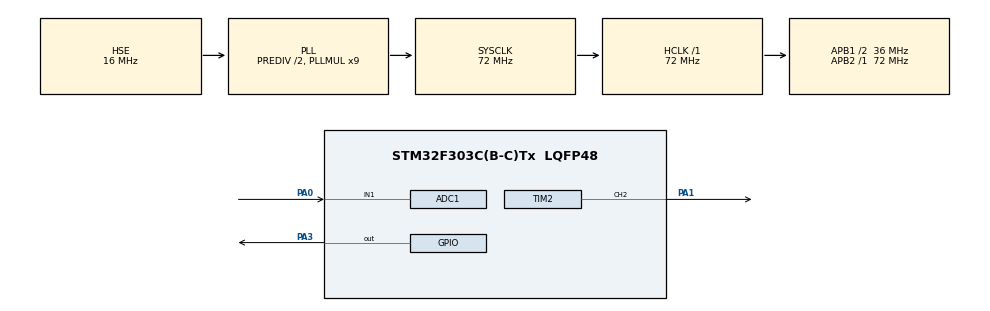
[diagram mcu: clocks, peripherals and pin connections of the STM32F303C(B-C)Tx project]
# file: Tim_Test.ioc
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ADC1.Channel-0\#ChannelRegularConversion=ADC_CHANNEL_1
ADC1.DMAContinuousRequests=ENABLE
ADC1.ExternalTrigConv=ADC_EXTERNALTRIGCONV_T3_TRGO
ADC1.NbrOfConversionFlag=1
ADC1.Offset-0\#ChannelRegularConversion=0
ADC1.OffsetNumber-0\#ChannelRegularConversion=ADC_OFFSET_NONE
ADC1.Rank-0\#ChannelRegularConversion=1
ADC1.SamplingTime-0\#ChannelRegularConversion=ADC_SAMPLETIME_1CYCLE_5
ADC1.SamplingTimeOPAMP-0\#ChannelRegularConversion=ADC_SAMPLETIME_61CYCLES_5
ADC1.master=1
Dma.ADC1.0.Direction=DMA_PERIPH_TO_MEMORY
Dma.ADC1.0.Instance=DMA1_Channel1
Dma.ADC1.0.MemDataAlignment=DMA_MDATAALIGN_HALFWORD
Dma.ADC1.0.MemInc=DMA_MINC_ENABLE
Dma.ADC1.0.Mode=DMA_CIRCULAR
Dma.ADC1.0.PeriphDataAlignment=DMA_PDATAALIGN_HALFWORD
Dma.ADC1.0.PeriphInc=DMA_PINC_DISABLE
Dma.ADC1.0.Priority=DMA_PRIORITY_LOW
Dma.Request0=ADC1
Mcu.Family=STM32F3
Mcu.Name=STM32F303C(B-C)Tx
Mcu.Package=LQFP48
NVIC.ADC1_2_IRQn=true\:0\:0\:false\:false\:true\:true\:true\:true
NVIC.DMA1_Channel1_IRQn=true\:0\:0\:false\:false\:true\:false\:true\:true
NVIC.PriorityGroup=NVIC_PRIORITYGROUP_4
PA0.Mode=IN1-Single-Ended
PA0.Signal=ADC1_IN1
PA1.GPIO_Speed=GPIO_SPEED_FREQ_HIGH
PA1.Signal=S_TIM2_CH2
PA3.Signal=GPIO_Output
PF0-OSC_IN.Mode=HSE-External-Oscillator
PF0-OSC_IN.Signal=RCC_OSC_IN
PF1-OSC_OUT.Mode=HSE-External-Oscillator
PF1-OSC_OUT.Signal=RCC_OSC_OUT
ProjectManager.HeapSize=0x200
ProjectManager.StackSize=0x400
ProjectManager.TargetToolchain=STM32CubeIDE
RCC.AHBFreq_Value=72000000
RCC.APB1CLKDivider=RCC_HCLK_DIV2
RCC.APB1Freq_Value=36000000
RCC.APB1TimFreq_Value=72000000
RCC.APB2Freq_Value=72000000
RCC.APB2TimFreq_Value=72000000
RCC.CortexFreq_Value=72000000
RCC.HCLKFreq_Value=72000000
RCC.HSE_VALUE=16000000
RCC.HSI_VALUE=8000000
RCC.LSE_VALUE=32768
RCC.PLLMUL=RCC_PLL_MUL9
RCC.PLLSourceVirtual=RCC_PLLSOURCE_HSE
RCC.RCC_PLLsource_Clock_Source_FROM_HSE=RCC_HSE_PREDIV_DIV2
RCC.SYSCLKFreq_VALUE=72000000
RCC.SYSCLKSourceVirtual=RCC_SYSCLKSOURCE_PLLCLK
RCC.USBFreq_Value=72000000
SH.S_TIM2_CH2.0=TIM2_CH2,PWM Generation2 CH2
TIM2.Channel-PWM\ Generation2\ CH2=TIM_CHANNEL_2
TIM2.Period=0
TIM3.Period=0
TIM3.TIM_MasterOutputTrigger=TIM_TRGO_UPDATE
VP_TIM2_VS_ClockSourceINT.Mode=Internal
VP_TIM3_VS_ClockSourceINT.Mode=Internal
board=custom

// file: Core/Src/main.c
/* USER CODE BEGIN Header */
/**
  ******************************************************************************
  * @file           : main.c
  * @brief          : Main program body
  ******************************************************************************
  * @attention
  *
  * Copyright (c) 2024 STMicroelectronics.
  * All rights reserved.
  *
  * This software is licensed under terms that can be found in the LICENSE file
  * in the root directory of this software component.
  * If no LICENSE file comes with this software, it is provided AS-IS.
  *
  ******************************************************************************
  */
/* USER CODE END Header */
#include "main.h"
#include "adc.h"
#include "dma.h"
#include "tim.h"
#include "gpio.h"

/* USER CODE BEGIN PV */
uint16_t data[10];
/* USER CODE END PV */

void SystemClock_Config(void);

int main(void)
{

  /* MCU Configuration--------------------------------------------------------*/

  /* Reset of all peripherals, Initializes the Flash interface and the Systick. */
  HAL_Init();

  /* Configure the system clock */
  SystemClock_Config();

  /* Initialize all configured peripherals */
  MX_GPIO_Init();
  MX_DMA_Init();
  MX_TIM2_Init();
  MX_ADC1_Init();
  MX_TIM3_Init();
  /* USER CODE BEGIN 2 */
  TIM2->ARR = 72-1;
  TIM2->PSC = 0;
  TIM2->CCR2 = 36-1;
  HAL_TIM_PWM_Start(&htim2, TIM_CHANNEL_2);

  HAL_GPIO_WritePin(GPIOA, GPIO_PIN_3, GPIO_PIN_SET);

  TIM3->ARR = 48-1;
  TIM3->PSC = 0;
  HAL_ADC_Start_DMA(&hadc1, (uint32_t*)&data, 10);
  HAL_TIM_Base_Start(&htim3);
  /* USER CODE END 2 */

  /* Infinite loop */
  while (1)
  {

  }
}

void SystemClock_Config(void)
{
  RCC_OscInitTypeDef RCC_OscInitStruct = {0};
  RCC_ClkInitTypeDef RCC_ClkInitStruct = {0};
  RCC_PeriphCLKInitTypeDef PeriphClkInit = {0};

  /** Initializes the RCC Oscillators according to the specified parameters
  * in the RCC_OscInitTypeDef structure.
  */
  RCC_OscInitStruct.OscillatorType = RCC_OSCILLATORTYPE_HSE;
  RCC_OscInitStruct.HSEState = RCC_HSE_ON;
  RCC_OscInitStruct.HSEPredivValue = RCC_HSE_PREDIV_DIV2;
  RCC_OscInitStruct.HSIState = RCC_HSI_ON;
  RCC_OscInitStruct.PLL.PLLState = RCC_PLL_ON;
  RCC_OscInitStruct.PLL.PLLSource = RCC_PLLSOURCE_HSE;
  RCC_OscInitStruct.PLL.PLLMUL = RCC_PLL_MUL9;
  if (HAL_RCC_OscConfig(&RCC_OscInitStruct) != HAL_OK)
  {
    Error_Handler();
  }

  /** Initializes the CPU, AHB and APB buses clocks
  */
  RCC_ClkInitStruct.ClockType = RCC_CLOCKTYPE_HCLK|RCC_CLOCKTYPE_SYSCLK
                              |RCC_CLOCKTYPE_PCLK1|RCC_CLOCKTYPE_PCLK2;
  RCC_ClkInitStruct.SYSCLKSource = RCC_SYSCLKSOURCE_PLLCLK;
  RCC_ClkInitStruct.AHBCLKDivider = RCC_SYSCLK_DIV1;
  RCC_ClkInitStruct.APB1CLKDivider = RCC_HCLK_DIV2;
  RCC_ClkInitStruct.APB2CLKDivider = RCC_HCLK_DIV1;

  if (HAL_RCC_ClockConfig(&RCC_ClkInitStruct, FLASH_LATENCY_2) != HAL_OK)
  {
    Error_Handler();
  }
  PeriphClkInit.PeriphClockSelection = RCC_PERIPHCLK_ADC12;
  PeriphClkInit.Adc12ClockSelection = RCC_ADC12PLLCLK_DIV1;
  if (HAL_RCCEx_PeriphCLKConfig(&PeriphClkInit) != HAL_OK)
  {
    Error_Handler();
  }
}

/* USER CODE BEGIN 4 */
void HAL_ADC_ConvCpltCallback(ADC_HandleTypeDef* hadc)
{
	HAL_GPIO_TogglePin(GPIOA, GPIO_PIN_3);
}
/* USER CODE END 4 */

void Error_Handler(void)
{
  __disable_irq();
  while (1)
  {
  }
}
